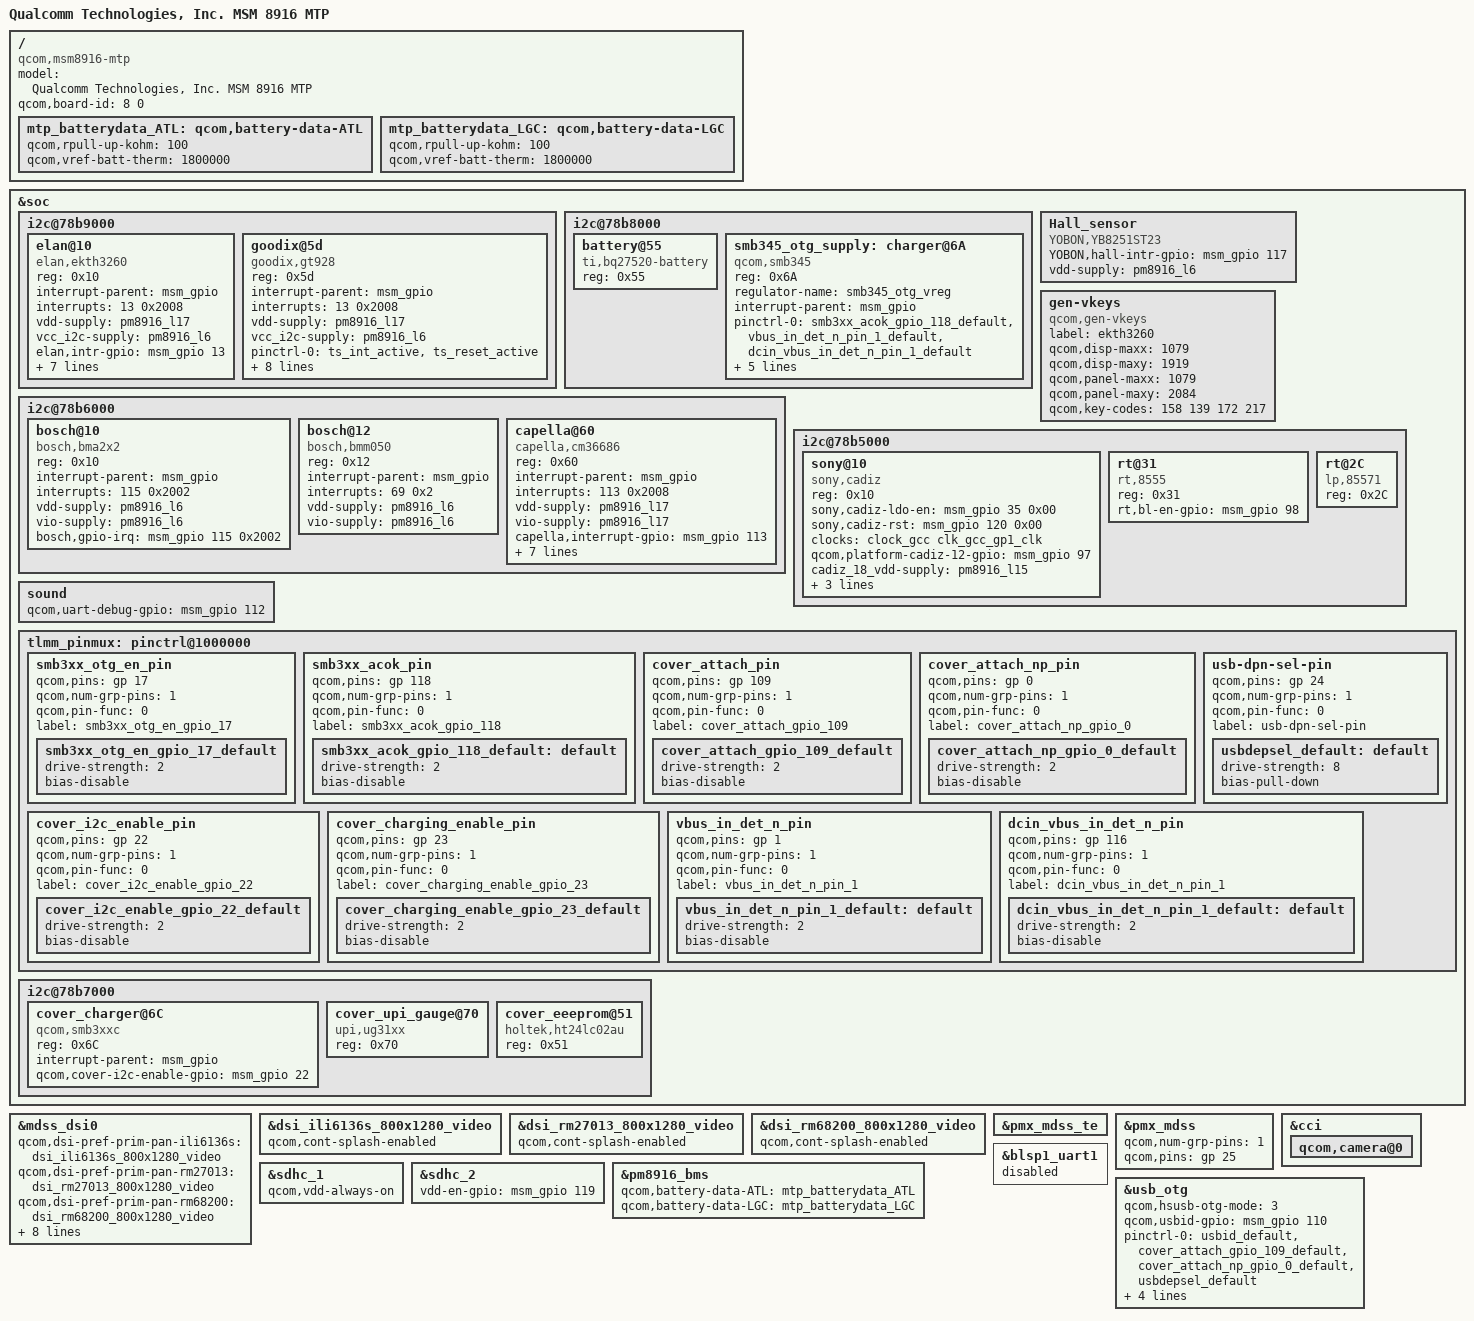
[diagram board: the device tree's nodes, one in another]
/* Copyright (c) 2014, The Linux Foundation. All rights reserved.
*
* This program is free software; you can redistribute it and/or modify
* it under the terms of the GNU General Public License version 2 and
* only version 2 as published by the Free Software Foundation.
*
* This program is distributed in the hope that it will be useful,
* but WITHOUT ANY WARRANTY; without even the implied warranty of
* MERCHANTABILITY or FITNESS FOR A PARTICULAR PURPOSE.  See the
* GNU General Public License for more details.
*/

/dts-v1/;

#include "msm8916-mtp.dtsi"
#include "msm8916-memory.dtsi"

/ {
	model = "Qualcomm Technologies, Inc. MSM 8916 MTP";
	compatible = "qcom,msm8916-mtp", "qcom,msm8916", "qcom,mtp";
	qcom,board-id = <8 0>;
};


/* ************* ASUS PROJECT Z380KL ************* */

/* Touch */
#include "msm8916-regulator.dtsi"
&soc {
	i2c@78b9000 { /* BLSP1 QUP5 */
		elan@10 {
			compatible = "elan,ekth3260";
			reg = <0x10>;
			interrupt-parent = <&msm_gpio>;
			interrupts = <13 0x2008>;
			vdd-supply = <&pm8916_l17>;
			vcc_i2c-supply = <&pm8916_l6>;
			/* pins used by touchscreen */
			elan,intr-gpio = <&msm_gpio 13 0x2008>;
			elan,reset-gpio = <&msm_gpio 12 0x0>;
			elan,power-gpio = <&msm_gpio 21 0x0>;
			elan,lcmid0-gpio = <&msm_gpio 100 0x0>;
			elan,lcmid2-gpio = <&msm_gpio 102 0x0>;
			elan,display-coords = <0 0 719 1279>;
			elan,panel-coords = <0 0 719 1405>;
			elan,i2c-pull-up;
		};
	};

   	i2c@78b9000 { /* BLSP1 QUP5 */
                goodix@5d {
                        compatible = "goodix,gt928";
                        reg = <0x5d>;
                        interrupt-parent = <&msm_gpio>;
                        interrupts = <13 0x2008>;
                        vdd-supply = <&pm8916_l17>;
                        vcc_i2c-supply = <&pm8916_l6>;
                        /* pins used by touchscreen */
                        pinctrl-names = "gt928_init_default","gt928_init_suspend";
                        pinctrl-0 = <&ts_int_active &ts_reset_active>;
                        pinctrl-1 = <&ts_int_suspend &ts_reset_suspend>;
                        pinctrl-2 = <&ts_release>;
                        goodix,intr-gpio = <&msm_gpio 13 0x2008>;
                        goodix,reset-gpio = <&msm_gpio 12 0x0>;
                        goodix,display-coords = <0 0 719 1279>;
                        goodix,panel-coords = <0 0 719 1405>;
                        goodix,product-id = <928>;
                        goodix,i2c-pull-up;
                };
        };

	i2c@78b8000 { /* BLSP1 QUP4 */
		battery@55 {
			compatible = "ti,bq27520-battery";
			reg = <0x55>;
		};
	};
	
	i2c@78b6000 { /* BLSP1 QUP2 */
		bosch@10 { /* Accelerometer sensor */
			compatible = "bosch,bma2x2";
			reg = <0x10>;
			pinctrl-names = "default";
			interrupt-parent = <&msm_gpio>;
			interrupts = <115 0x2002>;
			vdd-supply = <&pm8916_l6>;
			vio-supply = <&pm8916_l6>;
			bosch,gpio-irq = <&msm_gpio 115 0x2002>;
		};

		bosch@12 { /* Magnetic field sensor */
			compatible = "bosch,bmm050";
			reg = <0x12>;
			interrupt-parent = <&msm_gpio>;
			interrupts = <69 0x2>;
			vdd-supply = <&pm8916_l6>;
			vio-supply = <&pm8916_l6>;
		};
		
		capella@60 { /* Proximity & Light Sensor */
			compatible = "capella,cm36686";
			reg = <0x60>;
			interrupt-parent = <&msm_gpio>;
			interrupts = <113 0x2008>;
			vdd-supply = <&pm8916_l17>;
			vio-supply = <&pm8916_l17>;
			capella,interrupt-gpio = <&msm_gpio 113 0x2008>;
			capella,levels = <0x02 0x0f 0x1e 0x32 0x64 0xC8 0x12C 0x190 0x1F4 0x28A 0x320 0x3E8 0x5DC 0x7D0 0xBB8 0xFA0 0x1388 0x1B58 0x2710 0x30D4 0x3A98 0x445C 0x4E20>;
			capella,ps_close_thd_set = <0x1e>;
			capella,ps_away_thd_set = <0x19>;
			capella,ls_cmd = <0x0045>; /* ALS_IT=80ms, INT_PERS=2*/
			capella,ps_conf1_val = <0x0037>;
			capella,ps_conf3_val = <0x0300>;
		};

	};
	
	Hall_sensor {
                compatible = "YOBON,YB8251ST23";
                YOBON,hall-intr-gpio = <&msm_gpio 117 0>;
                vdd-supply = <&pm8916_l6>;
        };
	
	gen-vkeys {
		compatible = "qcom,gen-vkeys";
		label = "ekth3260";
		qcom,disp-maxx = <1079>;
		qcom,disp-maxy = <1919>;
		qcom,panel-maxx = <1079>;
		qcom,panel-maxy = <2084>;
		qcom,key-codes = <158 139 172 217>;
	};
};

/* Display */
#include "dsi-panel-ili6136s-800x1280-video.dtsi"
#include "dsi-panel-nt35521-800x1280-video.dtsi"
#include "dsi-panel-rm27013-800x1280-video.dtsi"
#include "dsi-panel-rm68200-800x1280-video.dtsi"

&mdss_dsi0 {
	qcom,dsi-pref-prim-pan-ili6136s = <&dsi_ili6136s_800x1280_video>;
	qcom,dsi-pref-prim-pan-rm27013 = <&dsi_rm27013_800x1280_video>;
	qcom,dsi-pref-prim-pan-rm68200 = <&dsi_rm68200_800x1280_video>;
	pinctrl-names = "mdss_default", "mdss_sleep";
	pinctrl-0 = <&mdss_dsi_active &mdss_te_active>;
	pinctrl-1 = <&mdss_dsi_suspend &mdss_te_suspend>;

	/delete-property/ qcom,platform-enable-gpio;
	qcom,platform-reset-gpio = <&msm_gpio 25 0>;
	/delete-property/ qcom,platform-bklight-en-gpio;

	// EVB ++++
	qcom,platform-enable-gpio-evb = <&msm_gpio 97 0>;
	qcom,platform-bklight-en-gpio-evb = <&msm_gpio 98 0>;
	// EVB ----

	qcom,platform-lcm-id2 = <&msm_gpio 102 0>;
	qcom,platform-lcm-id0 = <&msm_gpio 100 0>;
};

&dsi_ili6136s_800x1280_video {
	qcom,cont-splash-enabled;
};

&dsi_rm27013_800x1280_video {
	qcom,cont-splash-enabled;
};

&dsi_rm68200_800x1280_video {
	qcom,cont-splash-enabled;
};

&soc {
	i2c@78b5000 { /* BLSP1 QUP1 */
		sony@10 {
			compatible = "sony,cadiz";
			reg = <0x10>;
			sony,cadiz-ldo-en = <&msm_gpio 35 0x00>;
			sony,cadiz-rst = <&msm_gpio 120 0x00>;

			clocks = <&clock_gcc clk_gcc_gp1_clk>;
			clock-names = "ref_clk";

			qcom,platform-cadiz-12-gpio = <&msm_gpio 97 0>;
			cadiz_18_vdd-supply = <&pm8916_l15>;
			qcom,cadiz_18_vdd-voltage = <1800000 1800000>;

			tcon_ldo_vdd-supply = <&pm8916_l11>;
			qcom,tcon_ldo_vdd-voltage = <3300000 3300000>;
		};

		rt@31 {
			compatible = "rt,8555";
			reg = <0x31>;
			rt,bl-en-gpio = <&msm_gpio 98 0x00>;
		};

		rt@2C {
			compatible = "lp,85571";
			reg = <0x2C>;
		};
	};

        sound {
                qcom,uart-debug-gpio = <&msm_gpio 112 0>;
        };
};

&pmx_mdss_te {
	/delete-property/ qcom,num-grp-pins;
	/delete-property/ qcom,pins;
};

&pmx_mdss {
	qcom,num-grp-pins = <1>;
	qcom,pins = <&gp 25>;
};

&cci {
	qcom,camera@0 {
		/delete-property/ gpios;
	};
};

&blsp1_uart1 {
	status = "disabled";
};

&sdhc_1 {
        qcom,vdd-always-on;
};

&sdhc_2 {
	/delete-property/ vdd-supply;
	vdd-en-gpio = <&msm_gpio 119 0>;
};
/* +++++++++++++++++++++++++ USB, Charger, Battery +++++++++++++++++++++++++ */
&soc {
	tlmm_pinmux: pinctrl@1000000 {
		smb3xx_otg_en_pin {
			qcom,pins = <&gp 17>;
			qcom,num-grp-pins = <1>;
			qcom,pin-func = <0>;
			label = "smb3xx_otg_en_gpio_17";
			smb3xx_otg_en_gpio_17_default: smb3xx_otg_en_gpio_17_default {
				drive-strength = <2>;
				bias-disable;
			};
		};

		smb3xx_acok_pin {
			qcom,pins = <&gp 118>;
			qcom,num-grp-pins = <1>;
			qcom,pin-func = <0>;
			label = "smb3xx_acok_gpio_118";
			smb3xx_acok_gpio_118_default: default {
				drive-strength = <2>;	/* 2 MA */
				bias-disable;
			};
		};

		cover_attach_pin {
			qcom,pins = <&gp 109>;
			qcom,num-grp-pins = <1>;
			qcom,pin-func = <0>;
			label = "cover_attach_gpio_109";
			cover_attach_gpio_109_default: cover_attach_gpio_109_default {
				drive-strength = <2>;	/* 2 MA */
				bias-disable;
			};
		};
		cover_attach_np_pin {
			qcom,pins = <&gp 0>;
			qcom,num-grp-pins = <1>;
			qcom,pin-func = <0>;
			label = "cover_attach_np_gpio_0";
			cover_attach_np_gpio_0_default: cover_attach_np_gpio_0_default {
				drive-strength = <2>;	/* 2 MA */
				bias-disable;
			};
		};
		usb-dpn-sel-pin {
			qcom,pins = <&gp 24>;
			qcom,num-grp-pins = <1>;
			qcom,pin-func = <0>;
			label = "usb-dpn-sel-pin";
			usbdepsel_default: default {
				drive-strength = <8>;
				bias-pull-down;
			};
		};

		cover_i2c_enable_pin {
			qcom,pins = <&gp 22>;
			qcom,num-grp-pins = <1>;
			qcom,pin-func = <0>;
			label = "cover_i2c_enable_gpio_22";
			cover_i2c_enable_gpio_22_default: cover_i2c_enable_gpio_22_default {
				drive-strength = <2>;	/* 2 MA */
				bias-disable;
			};
		};
		cover_charging_enable_pin {
			qcom,pins = <&gp 23>;
			qcom,num-grp-pins = <1>;
			qcom,pin-func = <0>;
			label = "cover_charging_enable_gpio_23";
			cover_charging_enable_gpio_23_default: cover_charging_enable_gpio_23_default {
				drive-strength = <2>;	/* 2 MA */
				bias-disable;
			};
		};

		vbus_in_det_n_pin {
			qcom,pins = <&gp 1>;
			qcom,num-grp-pins = <1>;
			qcom,pin-func = <0>;
			label = "vbus_in_det_n_pin_1";
			vbus_in_det_n_pin_1_default: default {
				drive-strength = <2>;	/* 2 MA */
				bias-disable;
			};
		};

		dcin_vbus_in_det_n_pin {
                        qcom,pins = <&gp 116>;
                        qcom,num-grp-pins = <1>;
                        qcom,pin-func = <0>;
                        label = "dcin_vbus_in_det_n_pin_1";
                        dcin_vbus_in_det_n_pin_1_default: default {
                        drive-strength = <2>;   /* 2 MA */
                        bias-disable;
                        };
		};
	};
	i2c@78b7000 { /* BLSP1 QUP3 */
		cover_charger@6C {
			compatible = "qcom,smb3xxc";
			reg = <0x6C>;
			interrupt-parent = <&msm_gpio>;

			/*
			pinctrl-names = "cover_attach_gpio_109_default";
			pinctrl-0 = <&cover_attach_gpio_109_default>;

			qcom,cover-attach-gpio = <&msm_gpio 109 0>;
			*/
			qcom,cover-i2c-enable-gpio = <&msm_gpio 22 0>;
		};
		cover_upi_gauge@70 {
			compatible = "upi,ug31xx";
			reg = <0x70>;
		};
		cover_eeeprom@51 {
			compatible = "holtek,ht24lc02au";
			reg = <0x51>;
		};
	};
	i2c@78b8000 { /* BLSP1 QUP4 */
		smb345_otg_supply: charger@6A {
			compatible = "qcom,smb345";
			reg = <0x6A>;
			regulator-name = "smb345_otg_vreg";
			interrupt-parent = <&msm_gpio>;

			pinctrl-names = "default";
			pinctrl-0 = <&smb3xx_acok_gpio_118_default &vbus_in_det_n_pin_1_default &dcin_vbus_in_det_n_pin_1_default>;

			qcom,vbus-in-det-n-gpio = <&msm_gpio 1 0>;
			qcom,smb-otg-en-gpio = <&msm_gpio 17 0>;
			qcom,smb-acok-gpio = <&msm_gpio 118 0>;
			qcom,cover-charging-enable-gpio = <&msm_gpio 23 0>;
			qcom,dcin-vbus-in-det-n-gpio = <&msm_gpio 116 0>;
		};
	};
};

/* Battery Characterization */
/ {
	mtp_batterydata_ATL: qcom,battery-data-ATL {
		qcom,rpull-up-kohm = <100>;
		qcom,vref-batt-therm = <1800000>;

		#include "ASUS_C11P1329_ATL_1862159_3948mAh_3p4COV_VBMS_Final.dtsi"
	};
	mtp_batterydata_LGC: qcom,battery-data-LGC {
		qcom,rpull-up-kohm = <100>;
		qcom,vref-batt-therm = <1800000>;

		#include "ASUS_C11P1329_LGC_1862159_3948mAh_VBMS_3p4COV_Final.dtsi"
	};
};

&pm8916_bms {
	status = "ok";
	qcom,battery-data-ATL = <&mtp_batterydata_ATL>;
	qcom,battery-data-LGC = <&mtp_batterydata_LGC>;
	/delete-property/ qcom,disable-bms;
};

&usb_otg {
	qcom,hsusb-otg-mode = <3>;
	qcom,usbid-gpio = <&msm_gpio 110 0>;
	pinctrl-names = "default";
	pinctrl-0 = <&usbid_default &cover_attach_gpio_109_default &cover_attach_np_gpio_0_default &usbdepsel_default >;
	vbus_otg-supply = <&smb345_otg_supply>;
       /* Asus customized for audio cover */
       qcom,usb_dpn_sel-gpio = <&msm_gpio 24 0>;
       qcom,cover_id-gpio = <&msm_gpio 109 0>;
       qcom,cover_id_np-gpio = <&msm_gpio 0 1>;
};
/* ------------------------- USB, Charger, Battery ------------------------- */
